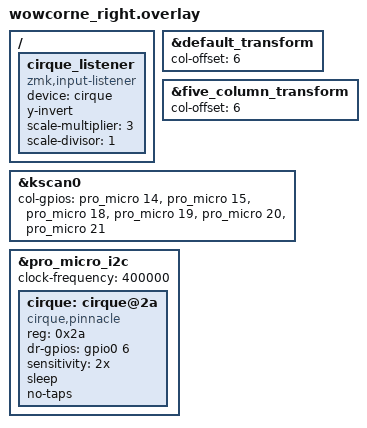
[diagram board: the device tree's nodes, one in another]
/*
 * Copyright (c) 2020 Pete Johanson
 *
 * SPDX-License-Identifier: MIT
 */

#include "wowcorne.dtsi"

&default_transform {
    col-offset = <6>;
};

&five_column_transform {
    col-offset = <6>;
};

&kscan0 {
    col-gpios
        = <&pro_micro 14 GPIO_ACTIVE_HIGH>
        , <&pro_micro 15 GPIO_ACTIVE_HIGH>
        , <&pro_micro 18 GPIO_ACTIVE_HIGH>
        , <&pro_micro 19 GPIO_ACTIVE_HIGH>
        , <&pro_micro 20 GPIO_ACTIVE_HIGH>
        , <&pro_micro 21 GPIO_ACTIVE_HIGH>
        ;
};

&pro_micro_i2c {
    status = "okay";
    clock-frequency = < 400000 >;
    cirque: cirque@2a {
        compatible = "cirque,pinnacle";
        reg = <0x2a>;
        status = "okay";
        dr-gpios = <&gpio0 6 (GPIO_ACTIVE_HIGH)>;
        sensitivity = "2x";
        sleep;
        no-taps;
    };
   };

/ {
  cirque_listener {
    compatible = "zmk,input-listener";
    device = <&cirque>;
    y-invert;
    scale-multiplier = <3>;
    scale-divisor = <1>;
  };
};

//&usbd {
//    status = "okay";
//    cdc_acm_uart: cdc_acm_uart {
//        compatible = "zephyr,cdc-acm-uart";
//    };
//};
